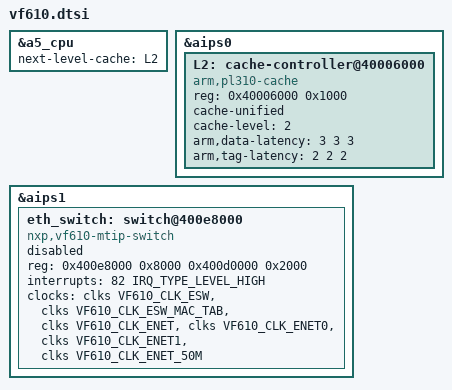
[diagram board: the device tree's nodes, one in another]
// SPDX-License-Identifier: (GPL-2.0 OR MIT)
//
// Copyright 2013 Freescale Semiconductor, Inc.

#include "vf500.dtsi"

&a5_cpu {
	next-level-cache = <&L2>;
};

&aips0 {
	L2: cache-controller@40006000 {
		compatible = "arm,pl310-cache";
		reg = <0x40006000 0x1000>;
		cache-unified;
		cache-level = <2>;
		arm,data-latency = <3 3 3>;
		arm,tag-latency = <2 2 2>;
	};
};

&aips1 {
	eth_switch: switch@400e8000 {
		compatible = "nxp,vf610-mtip-switch";
		reg = <0x400e8000 0x8000 0x400d0000 0x2000>;
		interrupts = <82 IRQ_TYPE_LEVEL_HIGH>;
		interrupt-names = "mtipl2sw";
		clocks = <&clks VF610_CLK_ESW>,
					<&clks VF610_CLK_ESW_MAC_TAB>,
					<&clks VF610_CLK_ENET>,
					<&clks VF610_CLK_ENET0>,
					<&clks VF610_CLK_ENET1>,
                                        <&clks VF610_CLK_ENET_50M>;
		clock-names = "esw", "esw_tab", "enet", "enet0", "enet1", "rmii-ref";
		status = "disabled";
	};
};
